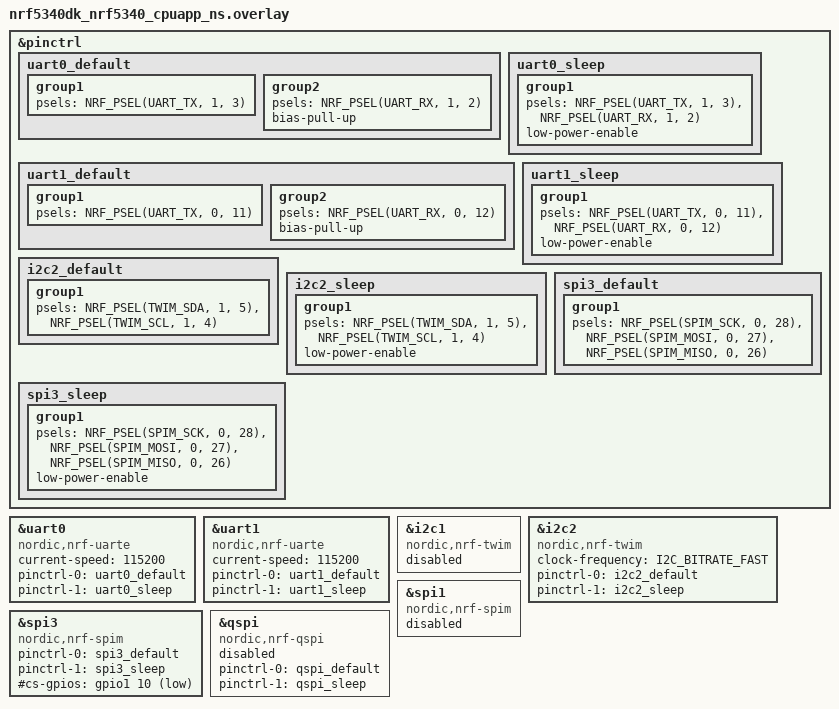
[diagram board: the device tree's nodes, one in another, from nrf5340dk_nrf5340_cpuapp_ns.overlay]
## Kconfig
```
menu "MQTT simple sample"
config APPLICATION_WORKQUEUE_STACK_SIZE
	int "Application workqueue stack size"
	default 1024

config APPLICATION_WORKQUEUE_PRIORITY
	int "Application workqueue priority"
	default SYSTEM_WORKQUEUE_PRIORITY
	
config MQTT_LOG_PUB_TOPIC
	string "MQTT log publish topic"
	default "device/e2/pushlog"

config MQTT_PUB_TOPIC
	string "MQTT publish topic"
	default "device/e2/pushdata"

config MQTT_SUB_TOPIC
	string "MQTT subscribe topic"
	default "my/subscribe/topic"

config MQTT_CLIENT_ID
	string "MQTT Client ID"
	default "my-client-id"

config MQTT_USER_NAME
	string "MQTT user name"
	default "admin123"
	
config MQTT_PASSWORD
	string "MQTT password"
	default "admin123"

config MQTT_DOMESTIC_BROKER_HOSTNAME
	string "MQTT broker hostname"
	default "mqtt.eclipse.org"

config MQTT_DOMESTIC_BROKER_PORT
	int "MQTT broker port"
	default 1883
	
config MQTT_FOREIGN_BROKER_HOSTNAME
	string "MQTT broker hostname"
	default "mqtt.eclipse.org"

config MQTT_FOREIGN_BROKER_PORT
	int "MQTT broker port"
	default 1883

config MQTT_MESSAGE_BUFFER_SIZE
	int "MQTT message buffer size"
	default 128

config MQTT_PAYLOAD_BUFFER_SIZE
	int "MQTT payload buffer size"
	default 128

config SEC_TAG
	int "Security tag to use for the connection"
	default 16842753

config PEER_VERIFY
	int "Peer verify parameter for mqtt_client"
	default 1
	help
		Set to 0 for VERIFY_NONE, 1 for VERIFY_OPTIONAL, and 2 for VERIFY_REQUIRED.

config MODEM_AUTO_REQUEST_POWER_SAVING_FEATURES
	bool "Auto request power saving features"
	default y

config LTE_EDRX_ENABLE
	bool "Enable LTE enhanced Discontinuous Reception"

config LTE_RAI_ENABLE
	bool "Enable LTE Release Assistance Indication"
endmenu

menu "WATCH DOG"
config WATCHDOG_TIMEOUT_MSEC
	int "Watchdog timeout in milliseconds"
	default 10000
endmenu

menu "ANIMATION"
config ANIMATION_SUPPORT
	bool "animation support"
	default n
endmenu #ANIMATION

menu "ANIMATION"
config ANIMATION_SUPPORT
	bool "animation support"
	default n
endmenu #ANIMATION

menu "TOUCH"
config TOUCH_SUPPORT
	bool "touch support"
	default n
endmenu #TOUCH

menu "WIFI"
config WIFI_SUPPORT
	bool "wifi support"
	default n
endmenu #WIFI

menu "PPG"
config PPG_SUPPORT
	bool "ppg support"
	default n
endmenu #PPG

menu "ECG"
config ECG_SUPPORT
	bool "ecg support"
	default n
endmenu #ECG

menu "IMU"
config IMU_SUPPORT
	bool "imu support"
	default n
config STEP_SUPPORT
	bool "step support"
	default n		
config SLEEP_SUPPORT
	bool "sleep support"
	default n		
config FALL_DETECT_SUPPORT
	bool "fall detect support"
	default n		
endmenu #IMU

menu "AUDIO"
config AUDIO_SUPPORT
	bool "ppg support"
	default n
endmenu #AUDIO

menu "BLE"
config BLE_SUPPORT
	bool "ble support"
	default n
endmenu #BLE

menu "SYNC"
config SYNC_SUPPORT
	bool "sync support"
	default n
endmenu #SYNC

menu "TEMPERATURE"
config TEMP_SUPPORT
	bool "temperature support"
	default n
endmenu #TEMPERATURE

menu "CRC"
config CRC_SUPPORT
	bool "crc check support"
	default n
endmenu #CRC

menu "DATA_DOWNLOAD"
config DATA_DOWNLOAD_SUPPORT
	bool "data download support"
	default n
config DATA_DOWNLOAD_HOST_CN
	string "Download host name(cn)"	
config DATA_DOWNLOAD_HOST_HK
	string "Download host name(hk)"	
# IMG	
config IMG_DATA_UPDATE
	bool "img update support"
	default n
config IMG_DATA_DOWNLOAD_FILE
	string "The file to download"

# FONT
config FONT_DATA_UPDATE
	bool "font update support"
	default n
config FONT_DATA_DOWNLOAD_FILE
	string "The file to download"

# PPG
config PPG_DATA_UPDATE
	bool "ppg update support"
	default n
config PPG_DATA_DOWNLOAD_FILE
	string "The file to download"

config USE_HTTPS
	bool
	prompt "Use HTTPS for download"
	depends on DOWNLOAD_CLIENT_TLS	
endmenu #DATA_DOWNLOAD 

menu "IMG_UPDATE"
config DL_TARGET_UI
	bool "img ui update support"
	default n
endmenu #IMG_UPDATE

menu "FOTA_MQTT"
config FOTA_DOWNLOAD
	bool "fota support"
	default n
	
config FOTA_DOWNLOAD_HOST_CN
	string "Download host name(cn)"

config FOTA_DOWNLOAD_HOST_HK
	string "Download host name(hk)"

config FOTA_DOWNLOAD_FILE
	string "The file to download"

config APPLICATION_VERSION
	int "Application version"
	default 1
endmenu #FOTA_MQTT

menu "BAT CODE"
config BARCODE_SUPPORT
	bool "bar code support"
	default n
endmenu #BAT CODE

menu "QR CODE"
config QRCODE_SUPPORT
	bool "qr code support"
	default n
endmenu #QR CODE

menu "WRIST CHECK"
config WRIST_CHECK_SUPPORT
	bool "wrist check support"
	default n
endmenu #WRIST CHECK

menu "FACTORY_TEST"
config FACTORY_TEST_SUPPORT
	bool "factory test support"
	default n
endmenu #FACTORY_TEST_SUPPORT

menu "FAST_KEY"
config FAST_KEY_SUPPORT
	bool "fast key support"
	default n
endmenu #FAST_KEY_SUPPORT

menu "ALARM_SUPPORT"
config ALARM_SUPPORT
	bool "alarm support"
	default n
endmenu #ALARM_SUPPORT

menu "Zephyr Kernel"
source "Kconfig.zephyr"
endmenu

module = APPLICATION_MODULE
module-str = Application module
source "subsys/logging/Kconfig.template.log_config"
```

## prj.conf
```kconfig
#
# Copyright (c) 2022 Nordic Semiconductor ASA
#
# SPDX-License-Identifier: LicenseRef-Nordic-5-Clause
#
# General config
CONFIG_NEWLIB_LIBC=y
CONFIG_NEWLIB_LIBC_FLOAT_PRINTF=y
CONFIG_ASSERT=y
CONFIG_REBOOT=y
CONFIG_GPIO=y
CONFIG_TRUSTED_EXECUTION_NONSECURE=y

# Log
CONFIG_LOG=y
CONFIG_USE_SEGGER_RTT=y
CONFIG_LOG_BACKEND_RTT=y
CONFIG_LOG_BACKEND_UART=n
CONFIG_LOG_DEFAULT_LEVEL=4
CONFIG_LOG_MODE_OVERFLOW=y
CONFIG_LOG_BACKEND_RTT_MODE_DROP=y
CONFIG_LOG_BACKEND_SHOW_COLOR=n
CONFIG_LOG_BACKEND_FORMAT_TIMESTAMP=n

# PinCtrl
CONFIG_PINCTRL=y
CONFIG_PINCTRL_NRF=y

# watch dog
CONFIG_WATCHDOG=y
CONFIG_WATCHDOG_TIMEOUT_MSEC=10000

# Fuel gauge
CONFIG_NRF_FUEL_GAUGE=y

# NVS
CONFIG_FLASH=y
CONFIG_FLASH_PAGE_LAYOUT=y
CONFIG_NVS=y
CONFIG_NVS_LOG_LEVEL_DBG=y
CONFIG_MPU_ALLOW_FLASH_WRITE=y

# Console
CONFIG_CONSOLE_SUBSYS=n
CONFIG_CONSOLE_HANDLER=n
CONFIG_CONSOLE_GETCHAR=n
CONFIG_CONSOLE=y
CONFIG_RTT_CONSOLE=y
CONFIG_UART_CONSOLE=n


# Library for buttons and LEDs
CONFIG_DK_LIBRARY=y

# Heap and stacks
CONFIG_HEAP_MEM_POOL_SIZE=16384
CONFIG_MAIN_STACK_SIZE=8192
CONFIG_SYSTEM_WORKQUEUE_STACK_SIZE=2048
CONFIG_HW_STACK_PROTECTION=y

# QSPI
CONFIG_NRFX_QSPI=y

# SPI
CONFIG_SPI=y

# I2C
CONFIG_I2C=y

# UART
CONFIG_SERIAL=y
CONFIG_UART_INTERRUPT_DRIVEN=y

# ECG
CONFIG_ECG_SUPPORT=n

# BLE
CONFIG_BLE_SUPPORT=n

# CRC Check
CONFIG_CRC_SUPPORT=n

# DEVICE POWER MANAGEMENT
CONFIG_PM_DEVICE=y

# Facotry test
CONFIG_FACTORY_TEST_SUPPORT=n
CONFIG_ENTROPY_GENERATOR=y
CONFIG_TEST_RANDOM_GENERATOR=y
```

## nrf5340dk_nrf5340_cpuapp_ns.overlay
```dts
/* SPDX-License-Identifier: Apache-2.0 */

&pinctrl
{
	uart0_default: uart0_default
	{
		group1
		{
			psels = <NRF_PSEL(UART_TX, 1, 3)>;
		};
		group2
		{
			psels = <NRF_PSEL(UART_RX, 1, 2)>;
			bias-pull-up;
		};
	};
	uart0_sleep: uart0_sleep
	{
		group1
		{
			psels = <NRF_PSEL(UART_TX, 1, 3)>,
							<NRF_PSEL(UART_RX, 1, 2)>;
			low-power-enable;
		};
	};
	
	uart1_default: uart1_default
	{
		group1
		{
			psels = <NRF_PSEL(UART_TX, 0, 11)>;
		};
		group2
		{
			psels = <NRF_PSEL(UART_RX, 0, 12)>;
			bias-pull-up;
		};
	};
	uart1_sleep: uart1_sleep
	{
		group1
		{
			psels = <NRF_PSEL(UART_TX, 0, 11)>,
							<NRF_PSEL(UART_RX, 0, 12)>;
			low-power-enable;
		};
	};
	
	i2c2_default: i2c2_default
	{
		group1
		{
			psels = <NRF_PSEL(TWIM_SDA, 1, 5)>,
							<NRF_PSEL(TWIM_SCL, 1, 4)>;
		};
	};
	i2c2_sleep: i2c2_sleep
	{
		group1
		{
			psels = <NRF_PSEL(TWIM_SDA, 1, 5)>,
							<NRF_PSEL(TWIM_SCL, 1, 4)>;
			low-power-enable;
		};
	};
	
	spi3_default: spi3_default
	{
		group1
		{
			psels = <NRF_PSEL(SPIM_SCK,  0, 28)>,
							<NRF_PSEL(SPIM_MOSI, 0, 27)>,
							<NRF_PSEL(SPIM_MISO, 0, 26)>;
		};
	};
	spi3_sleep: spi3_sleep
	{
		group1
		{
			psels = <NRF_PSEL(SPIM_SCK,  0, 28)>,
							<NRF_PSEL(SPIM_MOSI, 0, 27)>,
							<NRF_PSEL(SPIM_MISO, 0, 26)>;
			low-power-enable;
		};
	};
};


&uart0{
	compatible = "nordic,nrf-uarte";
	status = "okay";
	current-speed = <115200>;
	pinctrl-0 = <&uart0_default>;
	pinctrl-1 = <&uart0_sleep>;
	pinctrl-names = "default", "sleep";
};

&uart1{
	compatible = "nordic,nrf-uarte";
	status = "okay";
	current-speed = <115200>;
	pinctrl-0 = <&uart1_default>;
	pinctrl-1 = <&uart1_sleep>;
	pinctrl-names = "default", "sleep";
};

&i2c1{
	compatible = "nordic,nrf-twim";
	status = "disabled";
};

&i2c2{
	compatible = "nordic,nrf-twim";
	status = "okay";
	clock-frequency = <I2C_BITRATE_FAST>;
	pinctrl-0 = <&i2c2_default>;
	pinctrl-1 = <&i2c2_sleep>;
	pinctrl-names = "default", "sleep";
};

&spi1{
	compatible = "nordic,nrf-spim";
	status = "disabled";
};

&spi3{
	compatible = "nordic,nrf-spim";
	status = "okay";
	pinctrl-0 = <&spi3_default>;
	pinctrl-1 = <&spi3_sleep>;
	pinctrl-names = "default", "sleep";
	#cs-gpios = <&gpio1 10 GPIO_ACTIVE_LOW>;
};

&qspi{
	compatible = "nordic,nrf-qspi";
	status = "disabled";
	pinctrl-0 = <&qspi_default>;
	pinctrl-1 = <&qspi_sleep>;
	pinctrl-names = "default", "sleep";
};
```

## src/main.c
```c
/*
* Copyright (c) 2019 Nordic Semiconductor ASA
*
* SPDX-License-Identifier: LicenseRef-BSD-5-Clause-Nordic
*/

#include <zephyr/kernel.h>
#include <zephyr/device.h>
#include <stdio.h>
#include <zephyr/sys/printk.h>
#include <power/reboot.h>
#include <zephyr/drivers/spi.h>
#include <zephyr/drivers/gpio.h>
#include <dk_buttons_and_leds.h>
#include "datetime.h"
#include "inner_flash.h"
#include "external_flash.h"
#include "uart_ble.h"
#include "settings.h"
#include "pmu.h"
#include "codetrans.h"
#ifdef CONFIG_WATCHDOG
#include "watchdog.h"
#endif
#include "logger.h"

static bool sys_pwron_completed_flag = false;

static void modem_init(void)
{
	//nrf_modem_lib_init(NORMAL_MODE);
	//boot_write_img_confirmed();
}

void system_init(void)
{
	k_sleep(K_MSEC(500));//xb test 2022-03-11 启动时候延迟0.5S,等待其他外设完全启动

	modem_init();

	InitSystemSettings();

#ifdef CONFIG_PPG_SUPPORT
	//PPG_i2c_off();
#endif
	pmu_init();
	key_init();
	LCD_Init();
	//flash_init();
	
#ifdef CONFIG_PPG_SUPPORT	
	//PPG_init();
#endif
#ifdef CONFIG_ECG_SUPPORT
	//ECG_init();
#endif
	//ble_init();
	//LogInit();
}

void work_init(void)
{
	if(IS_ENABLED(CONFIG_WATCHDOG))
	{
		watchdog_init_and_start(&k_sys_work_q);
	}
}

bool system_is_completed(void)
{
	return sys_pwron_completed_flag;
}

void system_init_completed(void)
{
	if(!sys_pwron_completed_flag)
		sys_pwron_completed_flag = true;
}

/***************************************************************************
* 描  述 : main函数 
* 入  参 : 无 
* 返回值 : int 类型
**************************************************************************/
int main(void)
{
	LOGD("begin");

	work_init();
	system_init();
	
//	test_show_string();
//	test_show_image();
//	test_show_color();
//	test_show_stripe();
//	test_nvs();
//	test_flash();
//	test_uart_ble();
//	test_sensor();
//	test_show_digital_clock();
//	test_sensor();
//	test_pmu();
//	test_crypto();
//	test_imei_for_qr();
//	test_tp();
//	test_gps_on();
//	test_nb();
//	test_i2c();
//	test_bat_soc();
//	test_notify();
//	test_wifi();
//	LogInit();

	while(1)
	{
		KeyMsgProcess();
		TimeMsgProcess();
		PMUMsgProcess();
	#ifdef CONFIG_PPG_SUPPORT	
		PPGMsgProcess();
	#endif
	#ifdef CONFIG_ECG_SUPPORT
		ECGMsgProcess();
	#endif
		SettingsMsgPorcess();
		UartMsgProc();
	#ifdef CONFIG_FACTORY_TEST_SUPPORT
		FactoryTestProccess();
	#endif
		LogMsgProcess();
		system_init_completed();
		k_cpu_idle();
	}
}
```
